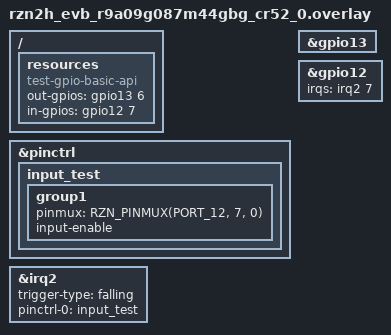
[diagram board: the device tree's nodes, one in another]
/*
 * Copyright (c) 2026 Renesas Electronics Corporation
 * SPDX-License-Identifier: Apache-2.0
 */

/ {
	resources {
		compatible = "test-gpio-basic-api";
		out-gpios = <&gpio13 6 GPIO_ACTIVE_HIGH>;
		in-gpios = <&gpio12 7 GPIO_ACTIVE_HIGH>;
	};
};

&pinctrl {
	input_test: input_test {
		group1 {
			pinmux = <RZN_PINMUX(PORT_12, 7, 0)>;
			input-enable;
		};
	};
};

&irq2 {
	trigger-type = "falling";
	pinctrl-0 = <&input_test>;
	pinctrl-names = "default";
	status = "okay";
};

&gpio13 {
	status = "okay";
};

&gpio12 {
	irqs = <&irq2 7>;
	status = "okay";
};
